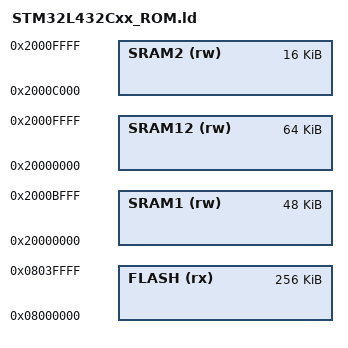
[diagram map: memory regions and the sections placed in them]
/* STM32L432Cxx — Cat43, 256K flash, USB line 32-pin — run from ROM.
   Generated by narray from MEMORY.periph, DO NOT EDIT. */

MEMORY
{
  FLASH  (rx) : ORIGIN = 0x8000000, LENGTH = 256K
  SRAM1  (rw) : ORIGIN = 0x20000000, LENGTH = 48K
  SRAM2  (rw) : ORIGIN = 0x2000C000, LENGTH = 16K  /* aliased at 0x10000000 */
  SRAM12 (rw) : ORIGIN = 0x20000000, LENGTH = 64K  /* SRAM1+SRAM2, contiguous */
}

REGION_ALIAS("TEXT", FLASH);  /* code & vectors in flash           */
REGION_ALIAS("DATA", SRAM1);  /* .data/.bss run in SRAM            */
REGION_ALIAS("LOAD", FLASH);  /* .data initialiser image in flash */
REGION_ALIAS("FAST", FLASH);  /* NARRAY_FAST code home            */
REGION_ALIAS("DMARAM", SRAM1);  /* NARRAY_DMABUF buffers */
REGION_ALIAS("SCRATCH", SRAM2);  /* stack + crash record  */

_estack = ORIGIN(SRAM2) + LENGTH(SRAM2); /* top of stack */

INCLUDE devs.ld      /* peripheral addresses (narray) */
INCLUDE sections.ld /* section layout (lib)          */
